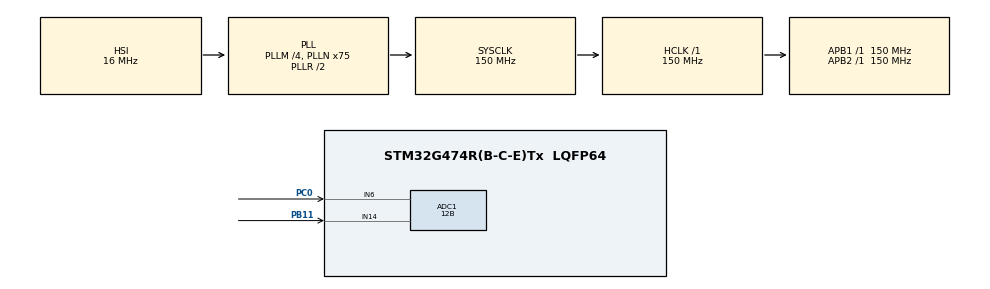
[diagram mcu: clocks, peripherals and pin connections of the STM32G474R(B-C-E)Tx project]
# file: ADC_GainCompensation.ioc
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ADC1.Channel-0\#ChannelRegularConversion=ADC_CHANNEL_6
ADC1.ClockPrescaler=ADC_CLOCK_SYNC_PCLK_DIV4
ADC1.ContinuousConvMode=DISABLE
ADC1.DMAContinuousRequests=ENABLE
ADC1.DataAlign=ADC_DATAALIGN_RIGHT
ADC1.DiscontinuousConvMode=DISABLE
ADC1.EOCSelection=ADC_EOC_SINGLE_CONV
ADC1.EnableAnalogWatchDog1=false
ADC1.EnableAnalogWatchDog2=false
ADC1.EnableAnalogWatchDog3=false
ADC1.EnableInjectedConversion=DISABLE
ADC1.EnableRegularConversion=ENABLE
ADC1.ExternalTrigConv=ADC_EXTERNALTRIG_T1_TRGO
ADC1.ExternalTrigConvEdge=ADC_EXTERNALTRIGCONVEDGE_RISING
ADC1.GainCompensation=VDDA_APPLI * GAIN_COMPENSATION_X1_FACTOR / DIGITAL_SCALE_12BITS
ADC1.LowPowerAutoWait=DISABLE
ADC1.Mode=ADC_MODE_INDEPENDENT
ADC1.NbrOfConversion=1
ADC1.OffsetNumber-0\#ChannelRegularConversion=ADC_OFFSET_NONE
ADC1.Overrun=ADC_OVR_DATA_OVERWRITTEN
ADC1.OversamplingMode=DISABLE
ADC1.Rank-0\#ChannelRegularConversion=1
ADC1.Resolution=ADC_RESOLUTION_12B
ADC1.SamplingTime-0\#ChannelRegularConversion=ADC_SAMPLETIME_640CYCLES_5
ADC1.ScanConvMode=ADC_SCAN_DISABLE
ADC1.master=1
Dma.ADC1.0.Direction=DMA_PERIPH_TO_MEMORY
Dma.ADC1.0.EventEnable=DISABLE
Dma.ADC1.0.Instance=DMA1_Channel1
Dma.ADC1.0.MemDataAlignment=DMA_MDATAALIGN_HALFWORD
Dma.ADC1.0.MemInc=DMA_MINC_ENABLE
Dma.ADC1.0.Mode=DMA_CIRCULAR
Dma.ADC1.0.PeriphDataAlignment=DMA_PDATAALIGN_HALFWORD
Dma.ADC1.0.PeriphInc=DMA_PINC_DISABLE
Dma.ADC1.0.Polarity=HAL_DMAMUX_REQ_GEN_RISING
Dma.ADC1.0.Priority=DMA_PRIORITY_MEDIUM
Dma.ADC1.0.RequestNumber=1
Dma.ADC1.0.SignalID=NONE
Dma.ADC1.0.SyncEnable=DISABLE
Dma.ADC1.0.SyncPolarity=HAL_DMAMUX_SYNC_NO_EVENT
Dma.ADC1.0.SyncRequestNumber=1
Dma.ADC1.0.SyncSignalID=NONE
Dma.Request0=ADC1
Mcu.Family=STM32G4
Mcu.Name=STM32G474R(B-C-E)Tx
Mcu.Package=LQFP64
NVIC.DMA1_Channel1_IRQn=true\:0\:0\:false\:false\:true\:false\:true\:true
NVIC.PriorityGroup=NVIC_PRIORITYGROUP_4
PB11.Mode=IN14-Single-Ended
PB11.Signal=ADC1_IN14
PC0.Mode=IN6-Single-Ended
PC0.Signal=ADC1_IN6
ProjectManager.HeapSize=0x200
ProjectManager.StackSize=0x400
ProjectManager.TargetToolchain=EWARM V8.32
RCC.ADC12Freq_Value=150000000
RCC.ADC345Freq_Value=150000000
RCC.AHBFreq_Value=150000000
RCC.APB1Freq_Value=150000000
RCC.APB1TimFreq_Value=150000000
RCC.APB2Freq_Value=150000000
RCC.APB2TimFreq_Value=150000000
RCC.CortexFreq_Value=150000000
RCC.EXTERNAL_CLOCK_VALUE=12288000
RCC.HCLKFreq_Value=150000000
RCC.HSE_VALUE=24000000
RCC.HSI48_VALUE=16000000
RCC.HSI_VALUE=16000000
RCC.LSE_VALUE=32768
RCC.PLLM=RCC_PLLM_DIV4
RCC.PLLN=75
RCC.SYSCLKFreq_VALUE=150000000
RCC.SYSCLKSource=RCC_SYSCLKSOURCE_PLLCLK
RCC.USBFreq_Value=150000000
RCC.VCOOutputFreq_Value=300000000
TIM1.AutoReloadPreload=TIM_AUTORELOAD_PRELOAD_DISABLE
TIM1.ClockDivision=TIM_CLOCKDIVISION_DIV1
TIM1.CounterMode=TIM_COUNTERMODE_UP
TIM1.Dithering=Disable
TIM1.PeriodNoDither=499
TIM1.Prescaler=149
TIM1.RepetitionCounter=0
TIM1.TIM_MasterOutputTrigger=TIM_TRGO_UPDATE
TIM1.TIM_MasterOutputTrigger2=TIM_TRGO2_RESET
TIM1.TIM_MasterSlaveMode=TIM_MASTERSLAVEMODE_DISABLE
VP_SYS_VS_DBSignals.Mode=DisableDeadBatterySignals
VP_TIM1_VS_ClockSourceINT.Mode=Internal
board=custom

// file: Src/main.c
/* USER CODE BEGIN Header */
/**
  ******************************************************************************
  * @file    Examples/ADC/ADC_GainCompensation/Src/main.c
  * @author  MCD Application Team
  * @brief   This example provides a short description of how to use the ADC
  *          peripheral with sequencer, to convert several channels.
  *          Channels converted are 1 channel on external pin and 2 internal
  *          channels (VrefInt and temperature sensor).
  *          Moreover, voltage and temperature are then computed.
  ******************************************************************************
  * @attention
  *
  * <h2><center>&copy; Copyright (c) 2019 STMicroelectronics.
  * All rights reserved.</center></h2>
  *
  * This software component is licensed by ST under BSD 3-Clause license,
  * the "License"; You may not use this file except in compliance with the
  * License. You may obtain a copy of the License at:
  *                        opensource.org/licenses/BSD-3-Clause
  *
  ******************************************************************************
  */
/* USER CODE END Header */
#include "main.h"

/* USER CODE BEGIN PD */
/* Definitions of environment analog values */
  /* Value of analog reference voltage (Vref+), connected to analog voltage   */
  /* supply Vdda (unit: mV).                                                  */
  #define VDDA_APPLI                       (3300U)
/* USER CODE END PD */

ADC_HandleTypeDef hadc1;
DMA_HandleTypeDef hdma_adc1;

TIM_HandleTypeDef htim1;

/* USER CODE BEGIN PV */
/* Private variables ---------------------------------------------------------*/
/* Variables for ADC conversion data computation to physical values */
__IO uint16_t uhADCxConvertedData_Voltage_mVolt = 0U;        /* Value of voltage on GPIO pin (on which is mapped ADC channel) calculated from ADC conversion data (unit: mV) */

/* USER CODE END PV */

void SystemClock_Config(void);
static void MX_GPIO_Init(void);
static void MX_DMA_Init(void);
static void MX_ADC1_Init(void);
static void MX_TIM1_Init(void);

int main(void)
{

  /* MCU Configuration--------------------------------------------------------*/

  /* Reset of all peripherals, Initializes the Flash interface and the Systick. */
  HAL_Init();

  /* Configure the system clock */
  SystemClock_Config();

  /* Initialize all configured peripherals */
  MX_GPIO_Init();
  MX_DMA_Init();
  MX_ADC1_Init();
  MX_TIM1_Init();
  /* USER CODE BEGIN 2 */
  uhADCxConvertedData_Voltage_mVolt = VAR_CONVERTED_DATA_INIT_VALUE;

  /* Initialize LED on board */
  BSP_LED_Init(LED2);

  /* Run the ADC calibration in single-ended mode */
  if (HAL_ADCEx_Calibration_Start(&hadc1, ADC_SINGLE_ENDED) != HAL_OK)
  {
    /* Calibration Error */
    Error_Handler();
  }
  /* USER CODE END 2 */

  /* Infinite loop */
  /* USER CODE BEGIN WHILE */

  /*## Start ADC conversions ###############################################*/
  /* Start ADC group regular conversion with DMA */
  if (HAL_ADC_Start_DMA(&hadc1,
                        (uint32_t *)&uhADCxConvertedData_Voltage_mVolt,
                        1
                       ) != HAL_OK)
  {
    /* ADC conversion start error */
    Error_Handler();
  }

  /* Start Timer trigger */
  if (HAL_TIM_Base_Start(&htim1) != HAL_OK)
  {
    /* Counter enable error */
    Error_Handler();
  }

  BSP_LED_On(LED2);
  while (1)
  {
    /* USER CODE END WHILE */

  }
}

void SystemClock_Config(void)
{
  RCC_OscInitTypeDef RCC_OscInitStruct = {0};
  RCC_ClkInitTypeDef RCC_ClkInitStruct = {0};
  RCC_PeriphCLKInitTypeDef PeriphClkInit = {0};

  /** Configure the main internal regulator output voltage
  */
  HAL_PWREx_ControlVoltageScaling(PWR_REGULATOR_VOLTAGE_SCALE1);
  /** Initializes the RCC Oscillators according to the specified parameters
  * in the RCC_OscInitTypeDef structure.
  */
  RCC_OscInitStruct.OscillatorType = RCC_OSCILLATORTYPE_HSI;
  RCC_OscInitStruct.HSIState = RCC_HSI_ON;
  RCC_OscInitStruct.HSICalibrationValue = RCC_HSICALIBRATION_DEFAULT;
  RCC_OscInitStruct.PLL.PLLState = RCC_PLL_ON;
  RCC_OscInitStruct.PLL.PLLSource = RCC_PLLSOURCE_HSI;
  RCC_OscInitStruct.PLL.PLLM = RCC_PLLM_DIV4;
  RCC_OscInitStruct.PLL.PLLN = 75;
  RCC_OscInitStruct.PLL.PLLP = RCC_PLLP_DIV2;
  RCC_OscInitStruct.PLL.PLLQ = RCC_PLLQ_DIV2;
  RCC_OscInitStruct.PLL.PLLR = RCC_PLLR_DIV2;
  if (HAL_RCC_OscConfig(&RCC_OscInitStruct) != HAL_OK)
  {
    Error_Handler();
  }
  /** Initializes the CPU, AHB and APB buses clocks
  */
  RCC_ClkInitStruct.ClockType = RCC_CLOCKTYPE_HCLK|RCC_CLOCKTYPE_SYSCLK
                              |RCC_CLOCKTYPE_PCLK1|RCC_CLOCKTYPE_PCLK2;
  RCC_ClkInitStruct.SYSCLKSource = RCC_SYSCLKSOURCE_PLLCLK;
  RCC_ClkInitStruct.AHBCLKDivider = RCC_SYSCLK_DIV1;
  RCC_ClkInitStruct.APB1CLKDivider = RCC_HCLK_DIV1;
  RCC_ClkInitStruct.APB2CLKDivider = RCC_HCLK_DIV1;

  if (HAL_RCC_ClockConfig(&RCC_ClkInitStruct, FLASH_LATENCY_4) != HAL_OK)
  {
    Error_Handler();
  }
  /** Initializes the peripherals clocks
  */
  PeriphClkInit.PeriphClockSelection = RCC_PERIPHCLK_ADC12;
  PeriphClkInit.Adc12ClockSelection = RCC_ADC12CLKSOURCE_SYSCLK;
  if (HAL_RCCEx_PeriphCLKConfig(&PeriphClkInit) != HAL_OK)
  {
    Error_Handler();
  }
}

static void MX_ADC1_Init(void)
{

  ADC_MultiModeTypeDef multimode = {0};
  ADC_ChannelConfTypeDef sConfig = {0};

  /** Common config
  */
  hadc1.Instance = ADC1;
  hadc1.Init.ClockPrescaler = ADC_CLOCK_SYNC_PCLK_DIV4;
  hadc1.Init.Resolution = ADC_RESOLUTION_12B;
  hadc1.Init.DataAlign = ADC_DATAALIGN_RIGHT;
  hadc1.Init.GainCompensation = VDDA_APPLI * GAIN_COMPENSATION_X1_FACTOR / DIGITAL_SCALE_12BITS;
  hadc1.Init.ScanConvMode = ADC_SCAN_DISABLE;
  hadc1.Init.EOCSelection = ADC_EOC_SINGLE_CONV;
  hadc1.Init.LowPowerAutoWait = DISABLE;
  hadc1.Init.ContinuousConvMode = DISABLE;
  hadc1.Init.NbrOfConversion = 1;
  hadc1.Init.DiscontinuousConvMode = DISABLE;
  hadc1.Init.ExternalTrigConv = ADC_EXTERNALTRIG_T1_TRGO;
  hadc1.Init.ExternalTrigConvEdge = ADC_EXTERNALTRIGCONVEDGE_RISING;
  hadc1.Init.DMAContinuousRequests = ENABLE;
  hadc1.Init.Overrun = ADC_OVR_DATA_OVERWRITTEN;
  hadc1.Init.OversamplingMode = DISABLE;
  if (HAL_ADC_Init(&hadc1) != HAL_OK)
  {
    Error_Handler();
  }
  /** Configure the ADC multi-mode
  */
  multimode.Mode = ADC_MODE_INDEPENDENT;
  if (HAL_ADCEx_MultiModeConfigChannel(&hadc1, &multimode) != HAL_OK)
  {
    Error_Handler();
  }
  /** Configure Regular Channel
  */
  sConfig.Channel = ADC_CHANNEL_6;
  sConfig.Rank = ADC_REGULAR_RANK_1;
  sConfig.SamplingTime = ADC_SAMPLETIME_640CYCLES_5;
  sConfig.SingleDiff = ADC_SINGLE_ENDED;
  sConfig.OffsetNumber = ADC_OFFSET_NONE;
  sConfig.Offset = 0;
  if (HAL_ADC_ConfigChannel(&hadc1, &sConfig) != HAL_OK)
  {
    Error_Handler();
  }

}

static void MX_TIM1_Init(void)
{

  TIM_ClockConfigTypeDef sClockSourceConfig = {0};
  TIM_MasterConfigTypeDef sMasterConfig = {0};

  htim1.Instance = TIM1;
  htim1.Init.Prescaler = 149;
  htim1.Init.CounterMode = TIM_COUNTERMODE_UP;
  htim1.Init.Period = 499;
  htim1.Init.ClockDivision = TIM_CLOCKDIVISION_DIV1;
  htim1.Init.RepetitionCounter = 0;
  htim1.Init.AutoReloadPreload = TIM_AUTORELOAD_PRELOAD_DISABLE;
  if (HAL_TIM_Base_Init(&htim1) != HAL_OK)
  {
    Error_Handler();
  }
  sClockSourceConfig.ClockSource = TIM_CLOCKSOURCE_INTERNAL;
  if (HAL_TIM_ConfigClockSource(&htim1, &sClockSourceConfig) != HAL_OK)
  {
    Error_Handler();
  }
  sMasterConfig.MasterOutputTrigger = TIM_TRGO_UPDATE;
  sMasterConfig.MasterOutputTrigger2 = TIM_TRGO2_RESET;
  sMasterConfig.MasterSlaveMode = TIM_MASTERSLAVEMODE_DISABLE;
  if (HAL_TIMEx_MasterConfigSynchronization(&htim1, &sMasterConfig) != HAL_OK)
  {
    Error_Handler();
  }

}

static void MX_DMA_Init(void)
{

  /* DMA controller clock enable */
  __HAL_RCC_DMAMUX1_CLK_ENABLE();
  __HAL_RCC_DMA1_CLK_ENABLE();

  /* DMA interrupt init */
  /* DMA1_Channel1_IRQn interrupt configuration */
  HAL_NVIC_SetPriority(DMA1_Channel1_IRQn, 0, 0);
  HAL_NVIC_EnableIRQ(DMA1_Channel1_IRQn);

}

static void MX_GPIO_Init(void)
{

  /* GPIO Ports Clock Enable */
  __HAL_RCC_GPIOC_CLK_ENABLE();
  __HAL_RCC_GPIOB_CLK_ENABLE();

}

void Error_Handler(void)
{
  /* USER CODE BEGIN Error_Handler_Debug */
  /* User can add his own implementation to report the HAL error return state */
  while(1)
  {
    /* Toggle LED2 */
    BSP_LED_Off(LED2);
    HAL_Delay(800);
    BSP_LED_On(LED2);
    HAL_Delay(10);
    BSP_LED_Off(LED2);
    HAL_Delay(180);
    BSP_LED_On(LED2);
    HAL_Delay(10);
  }
  /* USER CODE END Error_Handler_Debug */
}

#ifdef  USE_FULL_ASSERT
/**
  * @brief  Reports the name of the source file and the source line number
  *         where the assert_param error has occurred.
  * @param  file: pointer to the source file name
  * @param  line: assert_param error line source number
  * @retval None
  */
void assert_failed(uint8_t *file, uint32_t line)
{
  /* USER CODE BEGIN 6 */
  /* User can add his own implementation to report the file name and line number,
     tex: printf("Wrong parameters value: file %s on line %d\r\n", file, line) */
  Error_Handler();
  /* USER CODE END 6 */
}
#endif /* USE_FULL_ASSERT */

/************************ (C) COPYRIGHT STMicroelectronics *****END OF FILE****/
